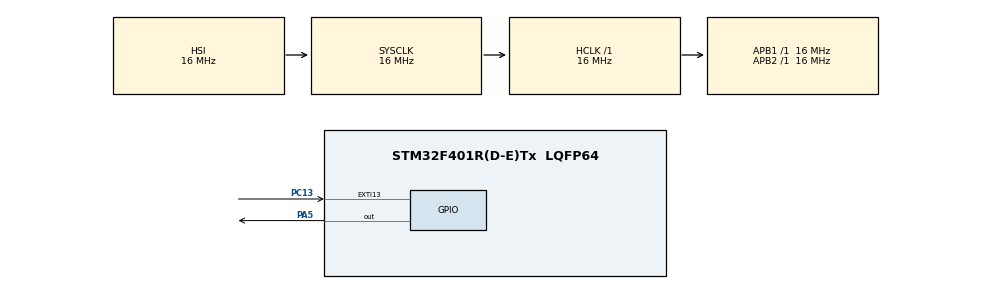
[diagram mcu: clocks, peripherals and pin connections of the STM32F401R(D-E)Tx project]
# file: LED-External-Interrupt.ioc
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Mcu.Family=STM32F4
RCC.CortexFreq_Value=16000000
PC13-ANTI_TAMP.GPIO_PuPd=GPIO_PULLUP
ProjectManager.StackSize=0x400
ProjectManager.TargetToolchain=MDK-ARM V5.27
TIM3.Period=20
RCC.LSE_VALUE=32768
RCC.AHBFreq_Value=16000000
NVIC.EXTI15_10_IRQn=true\:0\:0\:false\:false\:true\:true\:true
PA5.Signal=GPIO_Output
RCC.HSE_VALUE=25000000
board=custom
PC13-ANTI_TAMP.Signal=GPXTI13
RCC.VCOOutputFreq_Value=192000000
NVIC.TIM3_IRQn=true\:0\:0\:false\:false\:true\:true\:true
RCC.APB2Freq_Value=16000000
TIM3.Prescaler=16000
Mcu.Name=STM32F401R(D-E)Tx
RCC.SYSCLKFreq_VALUE=16000000
Mcu.Package=LQFP64
ProjectManager.HeapSize=0x200
RCC.HSI_VALUE=16000000
NVIC.PriorityGroup=NVIC_PRIORITYGROUP_4
RCC.APB1Freq_Value=16000000
VP_TIM3_VS_ClockSourceINT.Mode=Internal

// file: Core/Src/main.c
/* USER CODE BEGIN Header */
/**
  ******************************************************************************
  * @file           : main.c
  * @brief          : Main program body
  ******************************************************************************
  * @attention
  *
  * <h2><center>&copy; Copyright (c) 2020 STMicroelectronics.
  * All rights reserved.</center></h2>
  *
  * This software component is licensed by ST under BSD 3-Clause license,
  * the "License"; You may not use this file except in compliance with the
  * License. You may obtain a copy of the License at:
  *                        opensource.org/licenses/BSD-3-Clause
  *
  ******************************************************************************
  */
/* USER CODE END Header */
#include "main.h"

TIM_HandleTypeDef htim3;

/* USER CODE BEGIN PV */
uint8_t state = 1;
/* USER CODE END PV */

void SystemClock_Config(void);
static void MX_GPIO_Init(void);
static void MX_TIM3_Init(void);
/* USER CODE BEGIN PFP */
void HAL_GPIO_EXTI_Callback(uint16_t GPIO_Pin);
void HAL_TIM_PeriodElapsedCallback(TIM_HandleTypeDef *htim);
/* USER CODE END PFP */

int main(void)
{

  /* MCU Configuration--------------------------------------------------------*/

  /* Reset of all peripherals, Initializes the Flash interface and the Systick. */
  HAL_Init();

  /* Configure the system clock */
  SystemClock_Config();

  /* Initialize all configured peripherals */
  MX_GPIO_Init();
  MX_TIM3_Init();

  /* Infinite loop */
  while (1)
  {

  }
}

void SystemClock_Config(void)
{
  RCC_OscInitTypeDef RCC_OscInitStruct = {0};
  RCC_ClkInitTypeDef RCC_ClkInitStruct = {0};

  /** Configure the main internal regulator output voltage
  */
  __HAL_RCC_PWR_CLK_ENABLE();
  __HAL_PWR_VOLTAGESCALING_CONFIG(PWR_REGULATOR_VOLTAGE_SCALE2);
  /** Initializes the RCC Oscillators according to the specified parameters
  * in the RCC_OscInitTypeDef structure.
  */
  RCC_OscInitStruct.OscillatorType = RCC_OSCILLATORTYPE_HSI;
  RCC_OscInitStruct.HSIState = RCC_HSI_ON;
  RCC_OscInitStruct.HSICalibrationValue = RCC_HSICALIBRATION_DEFAULT;
  RCC_OscInitStruct.PLL.PLLState = RCC_PLL_NONE;
  if (HAL_RCC_OscConfig(&RCC_OscInitStruct) != HAL_OK)
  {
    Error_Handler();
  }
  /** Initializes the CPU, AHB and APB buses clocks
  */
  RCC_ClkInitStruct.ClockType = RCC_CLOCKTYPE_HCLK|RCC_CLOCKTYPE_SYSCLK
                              |RCC_CLOCKTYPE_PCLK1|RCC_CLOCKTYPE_PCLK2;
  RCC_ClkInitStruct.SYSCLKSource = RCC_SYSCLKSOURCE_HSI;
  RCC_ClkInitStruct.AHBCLKDivider = RCC_SYSCLK_DIV1;
  RCC_ClkInitStruct.APB1CLKDivider = RCC_HCLK_DIV1;
  RCC_ClkInitStruct.APB2CLKDivider = RCC_HCLK_DIV1;

  if (HAL_RCC_ClockConfig(&RCC_ClkInitStruct, FLASH_LATENCY_0) != HAL_OK)
  {
    Error_Handler();
  }
}

static void MX_TIM3_Init(void)
{

  TIM_ClockConfigTypeDef sClockSourceConfig = {0};
  TIM_MasterConfigTypeDef sMasterConfig = {0};

  htim3.Instance = TIM3;
  htim3.Init.Prescaler = 16000;
  htim3.Init.CounterMode = TIM_COUNTERMODE_UP;
  htim3.Init.Period = 20;
  htim3.Init.ClockDivision = TIM_CLOCKDIVISION_DIV1;
  htim3.Init.AutoReloadPreload = TIM_AUTORELOAD_PRELOAD_DISABLE;
  if (HAL_TIM_Base_Init(&htim3) != HAL_OK)
  {
    Error_Handler();
  }
  sClockSourceConfig.ClockSource = TIM_CLOCKSOURCE_INTERNAL;
  if (HAL_TIM_ConfigClockSource(&htim3, &sClockSourceConfig) != HAL_OK)
  {
    Error_Handler();
  }
  sMasterConfig.MasterOutputTrigger = TIM_TRGO_RESET;
  sMasterConfig.MasterSlaveMode = TIM_MASTERSLAVEMODE_DISABLE;
  if (HAL_TIMEx_MasterConfigSynchronization(&htim3, &sMasterConfig) != HAL_OK)
  {
    Error_Handler();
  }

}

static void MX_GPIO_Init(void)
{
  GPIO_InitTypeDef GPIO_InitStruct = {0};

  /* GPIO Ports Clock Enable */
  __HAL_RCC_GPIOC_CLK_ENABLE();
  __HAL_RCC_GPIOA_CLK_ENABLE();

  /*Configure GPIO pin Output Level */
  HAL_GPIO_WritePin(GPIOA, GPIO_PIN_5, GPIO_PIN_RESET);

  /*Configure GPIO pin : PC13 */
  GPIO_InitStruct.Pin = GPIO_PIN_13;
  GPIO_InitStruct.Mode = GPIO_MODE_IT_RISING;
  GPIO_InitStruct.Pull = GPIO_PULLUP;
  HAL_GPIO_Init(GPIOC, &GPIO_InitStruct);

  /*Configure GPIO pin : PA5 */
  GPIO_InitStruct.Pin = GPIO_PIN_5;
  GPIO_InitStruct.Mode = GPIO_MODE_OUTPUT_PP;
  GPIO_InitStruct.Pull = GPIO_NOPULL;
  GPIO_InitStruct.Speed = GPIO_SPEED_FREQ_LOW;
  HAL_GPIO_Init(GPIOA, &GPIO_InitStruct);

  /* EXTI interrupt init*/
  HAL_NVIC_SetPriority(EXTI15_10_IRQn, 0, 0);
  HAL_NVIC_EnableIRQ(EXTI15_10_IRQn);

}

/* USER CODE BEGIN 4 */
void HAL_GPIO_EXTI_Callback(uint16_t GPIO_Pin)
{
	if(GPIO_Pin == GPIO_PIN_13 && state == 1){
		HAL_TIM_Base_Start_IT(&htim3);
		state = 0;
	}
	else{
		__NOP();
	}
}

void HAL_TIM_PeriodElapsedCallback(TIM_HandleTypeDef *htim)
{
	if(HAL_GPIO_ReadPin(GPIOC, GPIO_PIN_13) == GPIO_PIN_RESET){
		HAL_GPIO_TogglePin(GPIOA, GPIO_PIN_5);
		state = 1;
		HAL_TIM_Base_Stop_IT(&htim3);
	}

}
/* USER CODE END 4 */

void Error_Handler(void)
{
}

/************************ (C) COPYRIGHT STMicroelectronics *****END OF FILE****/
